# DEBUGSS_DEBUGSS register map
Vendor: Texas Instruments
Registers are 32-bit, read-write, reset 0x0 unless marked. A register's access mark holds for its fields unless they carry their own. Offsets are as the file gives them; [hi:lo] are bit positions; {n}, {i} and the like mark numbered series; <NAME> marks a mode.

## DEBUGSS_DEBUGSS (part 2 of 3)
0x00 DEBUGSS_ONEMCU_APB_BASE ro
  [31:0] ONEMCU_APB_BASE — OneMCU APB Space : Start Address of ROM Table
0xFFC DEBUGSS_ONEMCU_APB_BASE_END ro
  [31:0] ONEMCU_APB_BASE_END — OneMCU APB Space : Endt Address of ROM Table
0x1000 DEBUGSS_ONEMCU_CTI_CONTROL
  [31:0] ONEMCU_CTI_CONTROL — http://infocenter.arm.com/help/topic/com.arm.doc.ddi0480e/CHDGDIHE.htmlhttp://infocenter.arm.com/help/topic/com.arm.doc.ddi0480e/CHDHBDIA.html
0x1010 DEBUGSS_ONEMCU_CTI_INTACK wo
  [31:0] ONEMCU_CTI_INTACK — Not Defined
0x1014 DEBUGSS_ONEMCU_CTI_APPSET
  [31:0] ONEMCU_CTI_APPSET — Not Defined
0x1018 DEBUGSS_ONEMCU_CTI_APPCLEAR wo
  [31:0] ONEMCU_CTI_APPCLEAR — Not Defined
0x101C DEBUGSS_ONEMCU_CTI_APPPULSE wo
  [31:0] ONEMCU_CTI_APPPULSE — Not Defined
{0x1020+4i} DEBUGSS_ONEMCU_CTI_INEN{i} (i=0..7)
  [31:0] ONEMCU_CTI_INEN{i} — Not Defined
{0x10A0+4i} DEBUGSS_ONEMCU_CTI_OUTEN{i} (i=0..7)
  [31:0] ONEMCU_CTI_OUTEN{i} — Not Defined
0x1130 DEBUGSS_ONEMCU_CTI_TRIGINSTATUS ro
  [31:0] ONEMCU_CTI_TRIGINSTATUS — Not Defined
0x1134 DEBUGSS_ONEMCU_CTI_TRIGOUTSTATUS ro
  [31:0] ONEMCU_CTI_TRIGOUTSTATUS — Not Defined
0x1138 DEBUGSS_ONEMCU_CTI_CHINSTATUS ro
  [31:0] ONEMCU_CTI_CHINSTATUS — Not Defined
0x113C DEBUGSS_ONEMCU_CTI_CHOUTSTATUS ro
  [31:0] ONEMCU_CTI_CHOUTSTATUS — Not Defined
0x1140 DEBUGSS_ONEMCU_CTI_GATE
  [31:0] ONEMCU_CTI_GATE — Not Defined
0x1144 DEBUGSS_ONEMCU_CTI_ASICCTL
  [31:0] ONEMCU_CTI_ASICCTL — Not Defined
0x1EDC DEBUGSS_ONEMCU_CTI_ITCHINACK wo
  [31:0] ONEMCU_CTI_ITCHINACK — Not Defined
0x1EE0 DEBUGSS_ONEMCU_CTI_ITTRIGINACK wo
  [31:0] ONEMCU_CTI_ITTRIGINACK — Not Defined
0x1EE4 DEBUGSS_ONEMCU_CTI_ITCHOUT wo
  [31:0] ONEMCU_CTI_ITCHOUT — Not Defined
0x1EE8 DEBUGSS_ONEMCU_CTI_ITTRIGOUT wo
  [31:0] ONEMCU_CTI_ITTRIGOUT — Not Defined
0x1EEC DEBUGSS_ONEMCU_CTI_ITCHOUTACK ro
  [31:0] ONEMCU_CTI_ITCHOUTACK — Not Defined
0x1EF0 DEBUGSS_ONEMCU_CTI_ITTRIGOUTACK ro
  [31:0] ONEMCU_CTI_ITTRIGOUTACK — Not Defined
0x1EF4 DEBUGSS_ONEMCU_CTI_ITCHIN ro
  [31:0] ONEMCU_CTI_ITCHIN — Not Defined
0x1EF8 DEBUGSS_ONEMCU_CTI_ITTRIGIN ro
  [31:0] ONEMCU_CTI_ITTRIGIN — Not Defined
0x1F00 DEBUGSS_ONEMCU_CTI_ITCTRL
  [31:0] ONEMCU_CTI_ITCTRL — Not Defined
0x1FA0 DEBUGSS_ONEMCU_CTI_CLAIM_TAG_SET
  [31:0] ONEMCU_CTI_CLAIM_TAG_SET — Not Defined
0x1FA4 DEBUGSS_ONEMCU_CTI_CLAIM_TAG_CLEAR
  [31:0] ONEMCU_CTI_CLAIM_TAG_CLEAR — Not Defined
0x1FB0 DEBUGSS_ONEMCU_CTI_LOCK_ACCESS_REGISTER wo
  [31:0] ONEMCU_CTI_LOCK_ACCESS_REGISTER — Not Defined
0x1FB4 DEBUGSS_ONEMCU_CTI_LOCK_STATUS_REGISTER ro
  [31:0] ONEMCU_CTI_LOCK_STATUS_REGISTER — Not Defined
0x1FB8 DEBUGSS_ONEMCU_CTI_AUTHENTICATION_STATUS ro
  [31:0] ONEMCU_CTI_AUTHENTICATION_STATUS — Not Defined
0x1FC8 DEBUGSS_ONEMCU_CTI_DEVICE_ID ro
  [31:0] ONEMCU_CTI_DEVICE_ID — Not Defined
0x1FCC DEBUGSS_ONEMCU_CTI_DEVICE_TYPE_IDENTIFIER ro
  [31:0] ONEMCU_CTI_DEVICE_TYPE_IDENTIFIER — Not Defined
{0x1FC0+4i} DEBUGSS_ONEMCU_CTI_PERIPHERALID{i} ro (i=4..7)
  [31:0] ONEMCU_CTI_PERIPHERALID{i} — Not Defined
{0x1FE0+4i} DEBUGSS_ONEMCU_CTI_PERIPHERALID{i} ro (i=0..3)
  [31:0] ONEMCU_CTI_PERIPHERALID{i} — Not Defined
{0x1FF0+4i} DEBUGSS_ONEMCU_CTI_COMPONENT_ID{i} ro (i=0..3)
  [31:0] ONEMCU_CTI_COMPONENT_ID{i} — Not Defined
0x2000 DEBUGSS_ONEMCU_TPIU_SPORTSZ ro reset 0xFFFFFFF
  [31:0] ONEMCU_TPIU_SPORTSZ — Supported port sizes
0x2004 DEBUGSS_ONEMCU_TPIU_CPORTSZ reset 0x1
  [31:0] ONEMCU_TPIU_CPORTSZ — Current port size
0x2100 DEBUGSS_ONEMCU_TPIU_STRIGM ro reset 0x11F
  [31:0] ONEMCU_TPIU_STRIGM — Supported trigger modes
0x2104 DEBUGSS_ONEMCU_TPIU_TRIGCNT
  [31:0] ONEMCU_TPIU_TRIGCNT — Trigger counter value
0x2108 DEBUGSS_ONEMCU_TPIU_TRIGMUL
  [31:0] ONEMCU_TPIU_TRIGMUL — Trigger multiplier
0x2200 DEBUGSS_ONEMCU_TPIU_STSTPTRN ro reset 0x3000F
  [31:0] ONEMCU_TPIU_STSTPTRN — Supported test pattern/modes
0x2204 DEBUGSS_ONEMCU_TPIU_CTSTPTRN
  [31:0] ONEMCU_TPIU_CTSTPTRN — Current test pattern/mode
0x2208 DEBUGSS_ONEMCU_TPIU_TPRCNTR
  [31:0] ONEMCU_TPIU_TPRCNTR — Test pattern repeat counter
0x2300 DEBUGSS_ONEMCU_TPIU_FFSTS ro reset 0x2
  [31:0] ONEMCU_TPIU_FFSTS — Formatter and flush status
0x2304 DEBUGSS_ONEMCU_TPIU_FFCTRL reset 0x1000
  [31:0] ONEMCU_TPIU_FFCTRL — Formatter and flush control
0x2308 DEBUGSS_ONEMCU_TPIU_FSCNTR reset 0x40
  [31:0] ONEMCU_TPIU_FSCNTR — Formatter synchronization counter
0x2400 DEBUGSS_ONEMCU_TPIU_EXCTLIN ro
  [31:0] ONEMCU_TPIU_EXCTLIN — EXTCTL In Port
0x2404 DEBUGSS_ONEMCU_TPIU_EXCTLOUT
  [31:0] ONEMCU_TPIU_EXCTLOUT — EXTCTL Out Port
0x2EE4 DEBUGSS_ONEMCU_TPIU_ITTRFLINACK wo
  [31:0] ONEMCU_TPIU_ITTRFLINACK — Integration Register, ITTRFLINACK
0x2EE8 DEBUGSS_ONEMCU_TPIU_ITTRFLIN ro
  [31:0] ONEMCU_TPIU_ITTRFLIN — Integration Register, ITTRFLIN
0x2EEC DEBUGSS_ONEMCU_TPIU_ITATBDATA0 ro
  [31:0] ONEMCU_TPIU_ITATBDATA0 — Integration Register, ITATBDATA0
0x2EF0 DEBUGSS_ONEMCU_TPIU_ITATBCTR2 wo
  [31:0] ONEMCU_TPIU_ITATBCTR2 — Integration Register, ITATBCTR2
0x2EF4 DEBUGSS_ONEMCU_TPIU_ITATBCTR1 ro
  [31:0] ONEMCU_TPIU_ITATBCTR1 — Integration Register, ITATBCTR1
0x2EF8 DEBUGSS_ONEMCU_TPIU_ITATBCTR0 ro
  [31:0] ONEMCU_TPIU_ITATBCTR0 — Integration Register, ITATBCTR0
0x2F00 DEBUGSS_ONEMCU_TPIU_ITCTRL
  [31:0] ONEMCU_TPIU_ITCTRL — Integration Mode Control Register
0x2FA0 DEBUGSS_ONEMCU_TPIU_CLAIMSET reset 0xF
  [31:0] ONEMCU_TPIU_CLAIMSET — Claim Tag Set
0x2FA4 DEBUGSS_ONEMCU_TPIU_CLAIMCLR
  [31:0] ONEMCU_TPIU_CLAIMCLR — Claim Tag Clear
0x2FB0 DEBUGSS_ONEMCU_TPIU_LAR ro
  [31:0] ONEMCU_TPIU_LAR — Lock status
0x2FB4 DEBUGSS_ONEMCU_TPIU_LSR wo
  [31:0] ONEMCU_TPIU_LSR — Lock Access
0x2FB8 DEBUGSS_ONEMCU_TPIU_AUTHSTATUS ro
  [31:0] ONEMCU_TPIU_AUTHSTATUS — Authentication status
0x2FC8 DEBUGSS_ONEMCU_TPIU_DEVID ro reset 0xA0
  [31:0] ONEMCU_TPIU_DEVID — Device ID
0x2FCC DEBUGSS_ONEMCU_TPIU_DEVTYPE ro reset 0x11
  [31:0] ONEMCU_TPIU_DEVTYPE — Device type identifier
0x2FD0 DEBUGSS_ONEMCU_TPIU_PIDR4 ro reset 0x4
  [31:0] ONEMCU_TPIU_PIDR4 — Peripheral ID4
{0x2FC0+4i} DEBUGSS_ONEMCU_TPIU_PIDR{i} ro (i=5..7)
  [31:0] ONEMCU_TPIU_PIDR{i} — Peripheral ID{i}
0x2FE0 DEBUGSS_ONEMCU_TPIU_PIDR0 ro reset 0x12
  [31:0] ONEMCU_TPIU_PIDR0 — Peripheral ID0
0x2FE4 DEBUGSS_ONEMCU_TPIU_PIDR1 ro reset 0xB9
  [31:0] ONEMCU_TPIU_PIDR1 — Peripheral ID1
0x2FE8 DEBUGSS_ONEMCU_TPIU_PIDR2 ro reset 0x3B
  [31:0] ONEMCU_TPIU_PIDR2 — Peripheral ID2
0x2FEC DEBUGSS_ONEMCU_TPIU_PIDR3 ro
  [31:0] ONEMCU_TPIU_PIDR3 — Peripheral ID3
0x2FF0 DEBUGSS_ONEMCU_TPIU_CIDR0 ro reset 0xD
  [31:0] ONEMCU_TPIU_CIDR0 — Component ID0
0x2FF4 DEBUGSS_ONEMCU_TPIU_CIDR1 ro reset 0x90
  [31:0] ONEMCU_TPIU_CIDR1 — Component ID1
0x2FF8 DEBUGSS_ONEMCU_TPIU_CIDR2 ro reset 0x5
  [31:0] ONEMCU_TPIU_CIDR2 — Component ID2
0x2FFC DEBUGSS_ONEMCU_TPIU_CIDR3 ro reset 0xB1
  [31:0] ONEMCU_TPIU_CIDR3 — Component ID3
0x10000 DEBUGSS_APB_EXT_PORT0_ROM
  [31:0] ATB_REPLICATOR_IDFILTER0 — http://infocenter.arm.com/help/topic/com.arm.doc.ddi0480e/CHDFGIED.htmlhttp://infocenter.arm.com/help/topic/com.arm.doc.ddi0480e/CHDBDCII.html
0x11000 DEBUGSS_ATB_REPLICATOR_IDFILTER0
  [31:0] ATB_REPLICATOR_IDFILTER1 — Not Defined
0x11004 DEBUGSS_ATB_REPLICATOR_IDFILTER1 ro
  [31:0] ATB_REPLICATOR_ITATBCTR1 — Not Defined
0x11EF8 DEBUGSS_ATB_REPLICATOR_ITATBCTR1 wo
  [31:0] ATB_REPLICATOR_ITATBCTR0 — Not Defined
0x11EFC DEBUGSS_ATB_REPLICATOR_ITATBCTR0
  [31:0] ATB_REPLICATOR_ITCTRL — Not Defined
0x11F00 DEBUGSS_ATB_REPLICATOR_ITCTRL reset 0xF
  [31:0] ATB_REPLICATOR_CLAIMSET — Not Defined
0x11FA0 DEBUGSS_ATB_REPLICATOR_CLAIMSET
  [31:0] ATB_REPLICATOR_CLAIMCLR — Not Defined
0x11FA4 DEBUGSS_ATB_REPLICATOR_CLAIMCLR wo
  [31:0] ATB_REPLICATOR_LAR — Not Defined
0x11FB0 DEBUGSS_ATB_REPLICATOR_LAR ro reset 0x3
  [31:0] ATB_REPLICATOR_LSR — Not Defined
0x11FB4 DEBUGSS_ATB_REPLICATOR_LSR ro
  [31:0] ATB_REPLICATOR_AUTHSTATUS — Not Defined
0x11FB8 DEBUGSS_ATB_REPLICATOR_AUTHSTATUS ro reset 0x2
  [31:0] ATB_REPLICATOR_DEVID — Not Defined
0x11FC8 DEBUGSS_ATB_REPLICATOR_DEVID ro reset 0x22
  [31:0] ATB_REPLICATOR_DEVTYPE — Not Defined
0x11FCC DEBUGSS_ATB_REPLICATOR_DEVTYPE ro reset 0x4
  [31:0] ATB_REPLICATOR_PIDR4 — Not Defined
0x11FD0 DEBUGSS_ATB_REPLICATOR_PIDR4 ro
  [31:0] ATB_REPLICATOR_RESERVED1 — Not Defined
0x11FD4 DEBUGSS_ATB_REPLICATOR_RESERVED1 ro
  [31:0] ATB_REPLICATOR_RESERVED2 — Not Defined
0x11FD8 DEBUGSS_ATB_REPLICATOR_RESERVED2 ro
  [31:0] ATB_REPLICATOR_RESERVED3 — Not Defined
0x11FDC DEBUGSS_ATB_REPLICATOR_RESERVED3 ro reset 0x9
  [31:0] ATB_REPLICATOR_PIDR0 — Not Defined
0x11FE0 DEBUGSS_ATB_REPLICATOR_PIDR0 ro reset 0xB9
  [31:0] ATB_REPLICATOR_PIDR1 — Not Defined
0x11FE4 DEBUGSS_ATB_REPLICATOR_PIDR1 ro reset 0x1B
  [31:0] ATB_REPLICATOR_PIDR2 — Not Defined
0x11FE8 DEBUGSS_ATB_REPLICATOR_PIDR2 ro
  [31:0] ATB_REPLICATOR_PIDR3 — Not Defined
0x11FEC DEBUGSS_ATB_REPLICATOR_PIDR3 ro reset 0xD
  [31:0] ATB_REPLICATOR_CIDR0 — Not Defined
0x11FF0 DEBUGSS_ATB_REPLICATOR_CIDR0 ro reset 0x90
  [31:0] ATB_REPLICATOR_CIDR1 — Not Defined
0x11FF4 DEBUGSS_ATB_REPLICATOR_CIDR1 ro reset 0x5
  [31:0] ATB_REPLICATOR_CIDR2 — Not Defined
0x11FF8 DEBUGSS_ATB_REPLICATOR_CIDR2 ro reset 0xB1
  [31:0] ATB_REPLICATOR_CIDR3 — Not Defined
0x11FFC DEBUGSS_ATB_REPLICATOR_CIDR3 ro
  [31:0] ETB_RDP — http://infocenter.arm.com/help/topic/com.arm.doc.ddi0480e/CHDIEIAJ.htmlhttp://infocenter.arm.com/help/topic/com.arm.doc.ddi0480e/CHDDBEHG.html
0x12004 DEBUGSS_ETB_RDP ro reset 0x8
  [31:0] ETB_STS — Not Defined
0x1200C DEBUGSS_ETB_STS ro
  [31:0] ETB_RRD — Not Defined
0x12010 DEBUGSS_ETB_RRD
  [31:0] ETB_RRP — Not Defined
0x12014 DEBUGSS_ETB_RRP
  [31:0] ETB_RWP — Not Defined
0x12018 DEBUGSS_ETB_RWP
  [31:0] ETB_TRG — Not Defined
0x1201C DEBUGSS_ETB_TRG
  [31:0] ETB_CTL — Not Defined
0x12020 DEBUGSS_ETB_CTL wo
  [31:0] ETB_RWD — Not Defined
0x12024 DEBUGSS_ETB_RWD ro reset 0x2
  [31:0] ETB_FFSR — Not Defined
0x12300 DEBUGSS_ETB_FFSR
  [31:0] ETB_FFCR — Not Defined
0x12304 DEBUGSS_ETB_FFCR wo
  [31:0] ETB_ITMISCOP0 — Not Defined
0x12EE0 DEBUGSS_ETB_ITMISCOP0 wo
  [31:0] ETB_ITTRFLINACK — Not Defined
0x12EE4 DEBUGSS_ETB_ITTRFLINACK ro
  [31:0] ETB_ITTRFLIN — Not Defined
0x12EE8 DEBUGSS_ETB_ITTRFLIN ro
  [31:0] ETB_ITATBDATA0 — Not Defined
0x12EEC DEBUGSS_ETB_ITATBDATA0 wo
  [31:0] ETB_ITATBCTR2 — Not Defined
0x12EF0 DEBUGSS_ETB_ITATBCTR2 ro
  [31:0] ETB_ITATBCTR1 — Not Defined
0x12EF4 DEBUGSS_ETB_ITATBCTR1 ro
  [31:0] ETB_ITATBCTR0 — Not Defined
0x12EF8 DEBUGSS_ETB_ITATBCTR0
  [31:0] ETB_ITCTRL — Not Defined
0x12F00 DEBUGSS_ETB_ITCTRL reset 0xF
  [31:0] ETB_CLAIMSET — Not Defined
0x12FA0 DEBUGSS_ETB_CLAIMSET
  [31:0] ETB_CLAIMCLR — Not Defined
0x12FA4 DEBUGSS_ETB_CLAIMCLR wo
  [31:0] ETB_LAR — Not Defined
0x12FB0 DEBUGSS_ETB_LAR ro reset 0x3
  [31:0] ETB_LSR — Not Defined
0x12FB4 DEBUGSS_ETB_LSR ro
  [31:0] ETB_AUTHSTATUS — Not Defined
0x12FB8 DEBUGSS_ETB_AUTHSTATUS ro
  [31:0] ETB_DEVID — Not Defined
0x12FC8 DEBUGSS_ETB_DEVID ro reset 0x21
  [31:0] ETB_DEVTYPE — Not Defined
0x12FCC DEBUGSS_ETB_DEVTYPE ro reset 0x4
  [31:0] ETB_PIDR4 — Not Defined
0x12FD0 DEBUGSS_ETB_PIDR4 ro
  [31:0] ETB_RESERVED4 — Not Defined
0x12FD4 DEBUGSS_ETB_RESERVED4 ro
  [31:0] ETB_RESERVED5 — Not Defined
0x12FD8 DEBUGSS_ETB_RESERVED5 ro
  [31:0] ETB_RESERVED6 — Not Defined
0x12FDC DEBUGSS_ETB_RESERVED6 ro reset 0x7
  [31:0] ETB_PIDR0 — Not Defined
0x12FE0 DEBUGSS_ETB_PIDR0 ro reset 0xB9
  [31:0] ETB_PIDR1 — Not Defined
0x12FE4 DEBUGSS_ETB_PIDR1 ro reset 0x3B
  [31:0] ETB_PIDR2 — Not Defined
0x12FE8 DEBUGSS_ETB_PIDR2 ro
  [31:0] ETB_PIDR3 — Not Defined
0x12FEC DEBUGSS_ETB_PIDR3 ro reset 0xD
  [31:0] ETB_CIDR0 — Not Defined
0x12FF0 DEBUGSS_ETB_CIDR0 ro reset 0x90
  [31:0] ETB_CIDR1 — Not Defined
0x12FF4 DEBUGSS_ETB_CIDR1 ro reset 0x5
  [31:0] ETB_CIDR2 — Not Defined
0x12FF8 DEBUGSS_ETB_CIDR2 ro reset 0xB1
  [31:0] ETB_CIDR3 — Not Defined
0x12FFC DEBUGSS_ETB_CIDR3 wo
  [31:0] STMDMASTARTR — ARM? System Trace Macrocell Programmers? ModelArchitecture Specification
0x13C04 DEBUGSS_STMDMASTARTR wo
  [31:0] STMDMASTOPR — ARM? System Trace Macrocell Programmers? ModelArchitecture Specification
0x13C08 DEBUGSS_STMDMASTOPR ro
  [31:0] STMDMASTATR — ARM? System Trace Macrocell Programmers? ModelArchitecture Specification
0x13C0C DEBUGSS_STMDMASTATR 8-bit
  [3:2] SENS — Determines the sensitivity of the DMA request to the current buffer level in the STM:0b00 Buffer is <25% full.0b01 Buffer is <50% full.0b10 Buffer is <75% full.0b11 Buffer is <100% full.
0x13C10 DEBUGSS_STMDMACTLR ro reset 0x2
  [31:0] STMDMAIDR — ARM? System Trace Macrocell Programmers? ModelArchitecture Specification
0x13CFC DEBUGSS_STMDMAIDR
  [31:0] STMHEER — ARM? System Trace Macrocell Programmers? ModelArchitecture Specification
0x13D00 DEBUGSS_STMHEER
  [31:0] STMHETER — ARM? System Trace Macrocell Programmers? ModelArchitecture Specification
0x13D20 DEBUGSS_STMHETER
  [31:0] STMHEBSR — ARM? System Trace Macrocell Programmers? ModelArchitecture Specification
0x13D60 DEBUGSS_STMHEBSR
  [31:0] STMHEMCR — ARM? System Trace Macrocell Programmers? ModelArchitecture Specification
0x13D64 DEBUGSS_STMHEMCR 8-bit
  [7:0] EXTMUX — Specifies the value that the optional external multiplexing logic uses to select the hardware events to connectto the STM.The value of this register is output from the STM on the HEEXTMUX[7:0] signals. The behavior of themultiplexing logic is IMPLEMENTATION DEFINED.This field is reset to zero.
0x13D68 DEBUGSS_STMHEEXTMUXR 16-bit ro reset 0x80
  [15:0] MASTER — The STPv2 master number for the hardware event trace:0x80 Hardware events are associated with master ID 0x80.
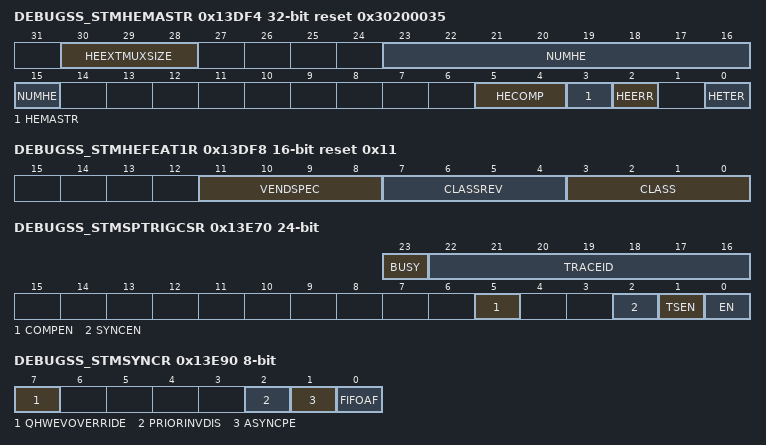
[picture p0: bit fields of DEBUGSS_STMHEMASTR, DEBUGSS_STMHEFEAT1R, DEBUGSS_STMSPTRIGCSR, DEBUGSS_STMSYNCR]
0x13DF4 DEBUGSS_STMHEMASTR ro reset 0x30200035
  [30:28] HEEXTMUXSIZE — The size of the STMHEEXTMUXR.EXTMUX bit field:0b011 8 bits wide.
  [23:15] NUMHE — The number of hardware events supported by the STM:0b001000000 64 hardware events.
  [5:4] HECOMP — Data compression on hardware event tracing support:0b11 Programmable data compression support. The STM implements theSTMHEMCR.COMPEN bit.
  [3] HEMASTR — Specifies the STMHEMASTR support:0b0 The STMHEMASTR is read-only.
  [2] HEERR — Hardware event error detection support:0b1 Implemented. The STM implements the STMHEMCR.ERRDETECT bit.
  [0] HETER — Specifies the STMHETER support:0b1 Implemented.
0x13DF8 DEBUGSS_STMHEFEAT1R 16-bit ro reset 0x11
  [11:8] VENDSPEC — Identifies vendor-specific modifications or mappings:0b0000 Vendor-specific information.
  [7:4] CLASSREV — Identifies the revision of the programmers model:0b0001 Revision.
  [3:0] CLASS — Identifies the programmers model:0b0001 Hardware event control.
0x13DFC DEBUGSS_STMHEIDR
  [31:0] STMSPER — ARM? System Trace Macrocell Programmers? ModelArchitecture Specification
0x13E00 DEBUGSS_STMSPER
  [31:0] STMSPTER — ARM? System Trace Macrocell Programmers? ModelArchitecture Specification
0x13E20 DEBUGSS_STMSPTER
  [31:0] STMSPSCR — ARM? System Trace Macrocell Programmers? ModelArchitecture Specification
0x13E60 DEBUGSS_STMSPSCR
  [31:0] STMSPMSCR — ARM? System Trace Macrocell Programmers? ModelArchitecture Specification
0x13E64 DEBUGSS_STMSPMSCR
  [31:0] STMSPOVERRIDER — ARM? System Trace Macrocell Programmers? ModelArchitecture Specification
0x13E68 DEBUGSS_STMSPOVERRIDER
  [31:0] STMSPMOVERRIDER — ARM? System Trace Macrocell Programmers? ModelArchitecture Specification
0x13E6C DEBUGSS_STMSPMOVERRIDER
  [31:0] STMSPTRIGCSR — ARM? System Trace Macrocell Programmers? ModelArchitecture Specification
0x13E70 DEBUGSS_STMSPTRIGCSR 24-bit
  [23] BUSY — Indicates whether the STM is busy, for example the STM trace FIFO is not empty:0b0 Not busy.0b1 Busy.
  [22:16] TRACEID — ATB trace ID. Setting this value to all zeroes or to a value greater than 0x6F might result in UNPREDICTABLEtracing. Reset value of this bit field is UNKNOWN.
  [5] COMPEN — Compression enable for stimulus ports:0b0 Disabled, the STM transmits data transfers based on the size of the transaction.0b1 Enabled, the STM compresses data transfers to save bandwidth.
  [2] SYNCEN — The STM implements the STMSYNCR, so this bit is Read As One.0b1 The STM implements the STMSYNCR.
  [1] TSEN — Determines whether to ignore timestamp requests:0b0 Disable timestamping. The STM ignores requests for timestamp generation, and treatsstimulus port writes that select timestamping as if timestamping were not selected.0b1 Enable timestamping. If stimulus writes select timestamping, the STM outputs a timestampaccording to STPv2.
  [0] EN — Global STM enable:0b0 Disabled0b1 Enabled.
0x13E80 DEBUGSS_STMTCSR wo
  [31:0] STMTSSTIMR — ARM? System Trace Macrocell Programmers? ModelArchitecture Specification
0x13E84 DEBUGSS_STMTSSTIMR
  [31:0] STMTSFREQR — ARM? System Trace Macrocell Programmers? ModelArchitecture Specification
0x13E8C DEBUGSS_STMTSFREQR
  [31:0] STMSYNCR — ARM? System Trace Macrocell Programmers? ModelArchitecture Specification
0x13E90 DEBUGSS_STMSYNCR 8-bit
  [7] QHWEVOVERRIDE — Low-power interface override when hardware event tracing is enabled:0b0 The STM can accept a quiescence request on the STM low-power interface whenthe STMHEMCR.EN bit is set to 0b1.0b1 If the STMHEMCR.EN bit is set to 0b1, all quiescence requests on the STMlow-power interface are denied.Reset value is 0b0.
  [2] PRIORINVDIS — Controls arbitration between the AXI interface and the hardware event observation interface duringflush:0b0 Priority inversion. When the AXI flush completes, the hardware event observationinterface gets priority until the hardware event observation interface flushcompletes.0b1 Priority inversion disabled. The AXI always has priority over the hardware eventobservation interface.Reset value is 0b0.
  [1] ASYNCPE — ASYNC priority:0b0 Always lower than trace.0b1 Escalates on second synchronization request.Reset value is 0b0.
  [0] FIFOAF — Auto-flush:0b0 Disabled.0b1 Enabled. The STM automatically drains all data even if the ATB interface is notfully utilized.Reset value is 0b0.
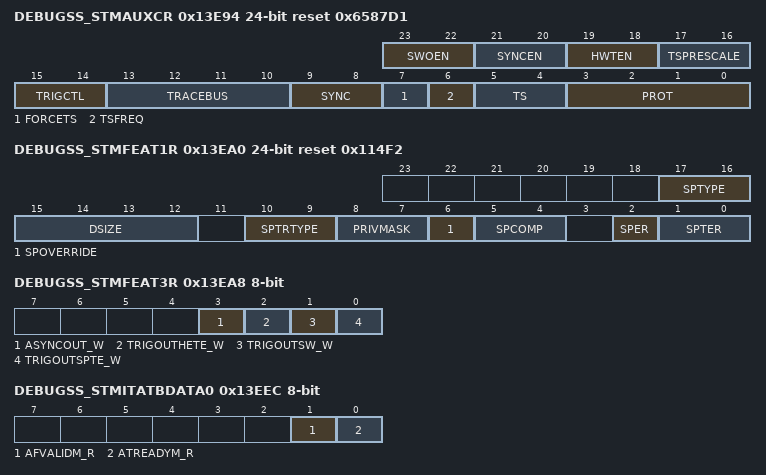
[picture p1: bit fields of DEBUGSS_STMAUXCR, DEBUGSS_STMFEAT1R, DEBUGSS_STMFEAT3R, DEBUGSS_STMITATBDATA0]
0x13E94 DEBUGSS_STMAUXCR 24-bit ro reset 0x6587D1
  [23:22] SWOEN — Specifies the STMTCSR.SWOEN bit support:0b01 Not implemented.
  [21:20] SYNCEN — Specifies the STMTCSR.SYNCEN bit support:0b10 Implemented but always reads as 0b1.
  [19:18] HWTEN — Specifies the STMTCSR.HWTEN bit support:0b01 Not implemented.
  [17:16] TSPRESCALE — Timestamp prescale support:0b01 Not implemented.
  [15:14] TRIGCTL — Trigger control support:0b10 Multi-shot and single-shot triggers supported, the STM implements the STMTRIGCSR.
  [13:10] TRACEBUS — Trace bus support:0b0001 CoreSight ATB plus ATB trigger support implemented, the STM implements theSTMTCSR.TRACEID and STMTRIGCSR.ATBTRIGEN bit fields.
  [9:8] SYNC — Specifies the STMSYNCR support:0b11 Implemented with MODE control.
  [7] FORCETS — Specifies the STMTSSTIMR support:0b1 The STM implements the STMTSSTIMR.FORCETS bit.
  [6] TSFREQ — Timestamp frequency indication configuration:0b1 The STMTSFREQR is read-write.
  [5:4] TS — Timestamp support:0b01 Absolute timestamps implemented.
  [3:0] PROT — Protocol:0b0001 STPv2 protocol.
0x13EA0 DEBUGSS_STMFEAT1R 24-bit ro reset 0x114F2
  [17:16] SPTYPE — Stimulus port type support:0b01 Only extended stimulus ports.
  [15:12] DSIZE — Fundamental data size:0b0001 64-bit data.
  [10:9] SPTRTYPE — Stimulus port transaction type support:0b10 Both invariant timing and guaranteed transactions.
  [8:7] PRIVMASK — Specifies the STMPRIVMASKR support:0b01 Not implemented.
  [6] SPOVERRIDE — Specifies the STMSPOVERRIDER support:0b1 STMSPOVERRIDER and STMSPMOVERRIDER implemented.
  [5:4] SPCOMP — Data compression on stimulus ports support:0b11 Data compression support is programmable, the STM implements theSTMTCSR.COMPEN bit.
  [2] SPER — Specifies the STMSPER presence:0b0 Implemented.
  [1:0] SPTER — Specifies the STMSPTER support:0b10 Implemented.
0x13EA4 DEBUGSS_STMFEAT2R 8-bit ro reset 0x7F
  [6:0] NUMMAST — The number of stimulus port masters implemented minus 1:0b1111111 128 ports.
0x13EA8 DEBUGSS_STMFEAT3R 8-bit wo
  [3] ASYNCOUT_W — Sets the value of the ASYNCOUT output signal in integration mode:0b1 Drive logic 0b1.0b0 Drive logic 0b0.
  [2] TRIGOUTHETE_W — Sets the value of the TRIGOUTHETE output signal in integration mode:0b1 Drive logic 0b1.0b0 Drive logic 0b0.
  [1] TRIGOUTSW_W — Sets the value of the TRIGOUTSW output signal in integration mode:0b1 Drive logic 0b1.0b0 Drive logic 0b0.
  [0] TRIGOUTSPTE_W — Sets the value of the TRIGOUTSPTE output signal in integration mode:0b1 Drive logic 0b1.0b0 Drive logic 0b0.
0x13EE8 DEBUGSS_STMITTRIGGER 8-bit wo
  [8] ATDATAM63_W — Sets the value of the ATDATAM[63] output signal:0b1 Drive logic 0b1.0b0 Drive logic 0b0.
  [7] ATDATAM55_W — Sets the value of the ATDATAM[55] output signal:0b1 Drive logic 0b1.0b0 Drive logic 0b0.
  [6] ATDATAM47_W — Sets the value of the ATDATAM[47] output signal:0b1 Drive logic 0b1.0b0 Drive logic 0b0.
  [5] ATDATAM39_W — Sets the value of the ATDATAM[39] output signal:0b1 Drive logic 0b1.0b0 Drive logic 0b0.
  [4] ATDATAM31_W — Sets the value of the ATDATAM[31] output signal:0b1 Drive logic 0b1.0b0 Drive logic 0b0.
  [3] ATDATAM23_W — Sets the value of the ATDATAM[23] output signal:0b1 Drive logic 0b1.0b0 Drive logic 0b0.
  [2] ATDATAM15_W — Sets the value of the ATDATAM[15] output signal:0b1 Drive logic 0b1.0b0 Drive logic 0b0.
  [1] ATDATAM7_W — Sets the value of the ATDATAM[7] output signal:0b1 Drive logic 0b1.0b0 Drive logic 0b0.
  [0] ATDATAM0_W — Sets the value of the ATDATAM[0] output signal:0b1 Drive logic 0b1.0b0 Drive logic 0b0.
0x13EEC DEBUGSS_STMITATBDATA0 8-bit ro
  [1] AFVALIDM_R — Reads the value of the AFVALIDM input signal:0b1 The signal is at logic 0b1.0b0 The signal is at logic 0b0.
  [0] ATREADYM_R — Reads the value of the ATREADYM input signal:0b1 The signal is at logic 0b1.0b0 The signal is at logic 0b0.
0x13EF0 DEBUGSS_STMITATBCTR2 8-bit wo
  [6:0] ATIDM_W — Sets the value of the ATIDM output signal.
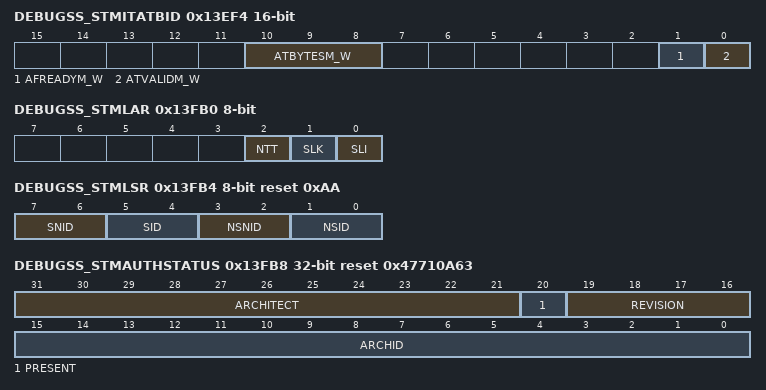
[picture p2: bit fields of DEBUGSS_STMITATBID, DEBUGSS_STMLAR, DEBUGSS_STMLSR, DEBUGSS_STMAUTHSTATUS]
0x13EF4 DEBUGSS_STMITATBID 16-bit wo
  [10:8] ATBYTESM_W — Sets the value of the ATBYTESM output signal:0b111 Drive logic 0b111.0b110 Drive logic 0b110.0b101 Drive logic 0b101.0b100 Drive logic 0b100.0b011 Drive logic 0b011.0b010 Drive logic 0b010.0b001 Drive logic 0b001.0b000 Drive logic 0b000.
  [1] AFREADYM_W — Sets the value of the AFREADYM output signal:0b1 Drive logic 0b1.0b0 Drive logic 0b0.
  [0] ATVALIDM_W — Sets the value of the ATVALIDM output signal:0b1 Drive logic 0b1.0b0 Drive logic 0b0.
0x13EF8 DEBUGSS_STMITATBCTR0 size not given
  [0] IME — Enables the component to switch between functional and integration mode.0b1 Enable integration mode.0b0 Disable integration mode.
0x13F00 DEBUGSS_STMITCTRL reset 0xF
  [31:0] STMCLAIMSET — ARM? System Trace Macrocell Programmers? ModelArchitecture Specification
0x13FA0 DEBUGSS_STMCLAIMSET
  [31:0] STMCLAIMCLR — ARM? System Trace Macrocell Programmers? ModelArchitecture Specification
0x13FA4 DEBUGSS_STMCLAIMCLR wo
  [31:0] KEY — Ignores writes when the PADDRDBG31 signal is HIGH.When the PADDRDBG31 signal is LOW, a write of 0xC5ACCE55 unlocks the lock control mechanism, enablingfurther writes with the PADDRDBG31 signal LOW.Other values lock the lock control mechanism, preventing further writes with the PADDRDBG31 signal LOW,except to the STMLAR.
0x13FB0 DEBUGSS_STMLAR 8-bit wo
  [2] NTT — Indicates whether the component implements the STMLAR as 8 bit or 32 bit.0b0 32 bit.
  [1] SLK — Returns the current status of the lock.0b0 Enables write access to the STM. For read accesses to the STMLSR when the PADDRDBG31signal is HIGH, this bit is always 0b0.0b1 Blocks write access to the STM. The STM ignores all write accesses to the registers when thePADDRDBG31 signal is LOW. Reads are permitted
  [0] SLI — Indicates that a lock control mechanism exists for the device.0b0 No lock control mechanism exists. The STM ignores writes to the STMLAR. For read accessesto the STMLSR when the PADDRDBG31 signal is HIGH, this bit is always 0b0.0b1 Lock control mechanism is present. For read accesses to the STMLSR when the PADDRDBG31signal is LOW, this bit is always 0b1.
0x13FB4 DEBUGSS_STMLSR 8-bit ro reset 0xAA
  [7:6] SNID — Indicates the security level for Secure non-invasive debug:0b10 Disabled.0b11 Enabled.
  [5:4] SID — Indicates the security level for Secure invasive debug:0b10 Disabled.0b11 Enabled.
  [3:2] NSNID — Indicates the security level for Non-secure non-invasive debug:0b10 Disabled.0b11 Enabled.
  [1:0] NSID — Indicates the security level for Non-secure invasive debug:0b10 Disabled.0b11 Enabled.
0x13FB8 DEBUGSS_STMAUTHSTATUS ro reset 0x47710A63
  [31:21] ARCHITECT — Defines the architect of the component:Bits[31:28] Indicates the JEP106 continuation code.Bits[27:21] Indicates the JEP106 identification code.See the Standard Manufacturer?s Identification Code for information about JEP106. For the STM-500,ARM is the architect, and this 11-bit field returns 0x23B.
  [20] PRESENT — Indicates the presence of the STMDEVARCH register:0b1 The STMDEVARCH register is present.
  [19:16] REVISION — Architecture revision. Returns the revision of the architecture that the ARCHID field specifies. For theSTM, this value is 0x1, indicating the STMv1.1 architecture.
  [15:0] ARCHID — Architecture ID. Returns a value that identifies the architecture of the component. For the STM, this valueis 0x0A63, indicating the STMv1.1 architecture.
0x13FBC DEBUGSS_STMDEVARCH 16-bit ro reset 0x10000
  [16:0] NUMSP — Indicates the number of stimulus ports implemented.0x10000 65536
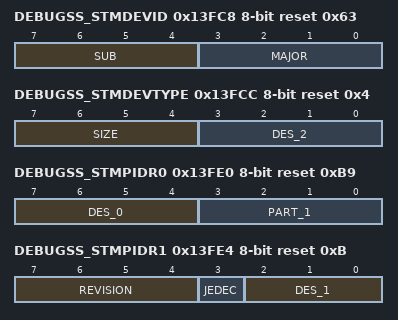
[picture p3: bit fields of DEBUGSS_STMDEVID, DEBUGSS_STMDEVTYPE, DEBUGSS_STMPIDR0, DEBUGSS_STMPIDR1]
0x13FC8 DEBUGSS_STMDEVID 8-bit ro reset 0x63
  [7:4] SUB — Sub-classification within the major category:0b0110 The component generates trace based on software and hardware stimulus
  [3:0] MAJOR — Major classification grouping for the debug or trace component:0b0011 The component is a trace source.
0x13FCC DEBUGSS_STMDEVTYPE 8-bit ro reset 0x4
  [7:4] SIZE — This 4-bit value indicates the total contiguous size of the memory window used by the component in powers oftwo from the standard 4KB. If a component only requires the standard 4KB, this bit field must read as 0x0, 4KBonly. For 8KB set to 0x1, for 16KB set to 0x2, for 32KB set to 0x3, and so on.0x0 The device only occupies 4KB of memory.
  [3:0] DES_2 — JEDEC continuation code indicating the designer of the component, together with the identity code.0x4 ARM JEDEC identity code is on the fifth bank.
0x13FD0 DEBUGSS_STMPIDR4 8-bit ro reset 0x63
  [7:0] PART_0 — Bits [7:0] of the component part number, specified by the designer of the component.0b01100011 Lowest eight bits of the part number, 0x963.
0x13FE0 DEBUGSS_STMPIDR0 8-bit ro reset 0xB9
  [7:4] DES_0 — Bits [3:0] of the JEDEC identity code indicating the designer of the component, together with the continuationcode.0b1011 Lowest four bits of the JEP106 identity code.
  [3:0] PART_1 — Bits [11:8] of the component part number, specified by the designer of the component.0b1001 Upper four bits of the part number, 0x963.
0x13FE4 DEBUGSS_STMPIDR1 8-bit ro reset 0xB
  [7:4] REVISION — An incremental value starting at 0x0 for the first design of this component. The value increases by one for bothmajor and minor revisions and is used as a look-up to establish the exact major and minor revision.0b0000 The device is at r0p0
  [3] JEDEC — Indicates the use of a JEDEC assigned value. This bit is always set.0b1 The designer ID is specified by JEDEC (http://www.jedec.org).
  [2:0] DES_1 — Bits [6:4] of the JEDEC identity code indicating the designer of the component, together with the continuationcode.0b011 Upper three bits of the JEP106 identity code
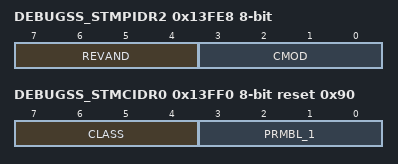
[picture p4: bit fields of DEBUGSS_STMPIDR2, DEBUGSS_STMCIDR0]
0x13FE8 DEBUGSS_STMPIDR2 8-bit ro
  [7:4] REVAND — Indicates minor errata fixes specific to the design, for example metal fixes after implementation. In most casesthis field is zero. ARM recommends that the component designers ensure that the bit field can be changed by ametal fix if required, for example by driving the bit field from registers that reset to zero.0x0 No metal fixes in the component.
  [3:0] CMOD — Where the component is reusable IP, this value indicates whether the customer has modified the behavior of thecomponent. In most cases this field is zero.0x0 No modifications made.
0x13FEC DEBUGSS_STMPIDR3 8-bit ro reset 0xD
  [7:0] PRMBL_0 — Contains bits [31:21] of the component identification.0x0D Identification value.
0x13FF0 DEBUGSS_STMCIDR0 8-bit ro reset 0x90
  [7:4] CLASS — Class of the component, for example, the ROM table or CoreSight component.0x9 Indicates the component is a CoreSight component.
  [3:0] PRMBL_1 — Contains bits [19:16] of the component identification.0x0 Identification value.
0x13FF4 DEBUGSS_STMCIDR1 8-bit ro reset 0x5
  [7:0] PRMBL_2 — Contains bits [15:8] of the component identification.0x05 Identification value.
0x13FF8 DEBUGSS_STMCIDR2 8-bit ro reset 0xB1
  [7:0] PRMBL_3 — Contains bits [7:0] of the component identification.0xB1 Identification value.
0x13FFC DEBUGSS_STMCIDR3
  [31:0] STM_CTI_CONTROL — Not Defined
0x14000 DEBUGSS_STM_CTI_CONTROL wo
  [31:0] STM_CTI_INTACK — Not Defined
0x14010 DEBUGSS_STM_CTI_INTACK
  [31:0] STM_CTI_APPSET — Not Defined
0x14014 DEBUGSS_STM_CTI_APPSET wo
  [31:0] STM_CTI_APPCLEAR — Not Defined
0x14018 DEBUGSS_STM_CTI_APPCLEAR wo
  [31:0] STM_CTI_APPPULSE — Not Defined
0x1401C DEBUGSS_STM_CTI_APPPULSE
  [31:0] STM_CTI_INEN0 — Not Defined
{0x14020+4i} DEBUGSS_STM_CTI_INEN{i} (i=0..6)
  [31:0] STM_CTI_INEN{i+1} — Not Defined
0x1403C DEBUGSS_STM_CTI_INEN7
  [31:0] STM_CTI_OUTEN0 — Not Defined
{0x140A0+4i} DEBUGSS_STM_CTI_OUTEN{i} (i=0..6)
  [31:0] STM_CTI_OUTEN{i+1} — Not Defined
0x140BC DEBUGSS_STM_CTI_OUTEN7 ro
  [31:0] STM_CTI_TRIGINSTATUS — Not Defined
0x14130 DEBUGSS_STM_CTI_TRIGINSTATUS ro
  [31:0] STM_CTI_TRIGOUTSTATUS — Not Defined
0x14134 DEBUGSS_STM_CTI_TRIGOUTSTATUS ro
  [31:0] STM_CTI_CHINSTATUS — Not Defined
0x14138 DEBUGSS_STM_CTI_CHINSTATUS ro
  [31:0] STM_CTI_CHOUTSTATUS — Not Defined
0x1413C DEBUGSS_STM_CTI_CHOUTSTATUS
  [31:0] STM_CTI_GATE — Not Defined
0x14140 DEBUGSS_STM_CTI_GATE
  [31:0] STM_CTI_ASICCTL — Not Defined
0x14144 DEBUGSS_STM_CTI_ASICCTL wo
  [31:0] STM_CTI_ITCHINACK — Not Defined
0x14EDC DEBUGSS_STM_CTI_ITCHINACK wo
  [31:0] STM_CTI_ITTRIGINACK — Not Defined
0x14EE0 DEBUGSS_STM_CTI_ITTRIGINACK wo
  [31:0] STM_CTI_ITCHOUT — Not Defined
0x14EE4 DEBUGSS_STM_CTI_ITCHOUT wo
  [31:0] STM_CTI_ITTRIGOUT — Not Defined
0x14EE8 DEBUGSS_STM_CTI_ITTRIGOUT ro
  [31:0] STM_CTI_ITCHOUTACK — Not Defined
0x14EEC DEBUGSS_STM_CTI_ITCHOUTACK ro
  [31:0] STM_CTI_ITTRIGOUTACK — Not Defined
0x14EF0 DEBUGSS_STM_CTI_ITTRIGOUTACK ro
  [31:0] STM_CTI_ITCHIN — Not Defined
0x14EF4 DEBUGSS_STM_CTI_ITCHIN ro
  [31:0] STM_CTI_ITTRIGIN — Not Defined
0x14EF8 DEBUGSS_STM_CTI_ITTRIGIN
  [31:0] STM_CTI_ITCTRL — Not Defined
0x14F00 DEBUGSS_STM_CTI_ITCTRL
  [31:0] STM_CTI_CLAIM_TAG_SET — Not Defined
0x14FA0 DEBUGSS_STM_CTI_CLAIM_TAG_SET
  [31:0] STM_CTI_CLAIM_TAG_CLEAR — Not Defined
0x14FA4 DEBUGSS_STM_CTI_CLAIM_TAG_CLEAR wo
  [31:0] STM_CTI_LOCK_ACCESS_REGISTER — Not Defined
0x14FB0 DEBUGSS_STM_CTI_LOCK_ACCESS_REGISTER ro
  [31:0] STM_CTI_LOCK_STATUS_REGISTER — Not Defined
0x14FB4 DEBUGSS_STM_CTI_LOCK_STATUS_REGISTER ro
  [31:0] STM_CTI_AUTHENTICATION_STATUS — Not Defined
0x14FB8 DEBUGSS_STM_CTI_AUTHENTICATION_STATUS ro
  [31:0] STM_CTI_DEVICE_ID — Not Defined
0x14FC8 DEBUGSS_STM_CTI_DEVICE_ID ro
  [31:0] STM_CTI_DEVICE_TYPE_IDENTIFIER — Not Defined
0x14FCC DEBUGSS_STM_CTI_DEVICE_TYPE_IDENTIFIER ro
  [31:0] STM_CTI_PERIPHERALID4 — Not Defined
{0x14FC0+4i} DEBUGSS_STM_CTI_PERIPHERALID{i} ro (i=4..6)
  [31:0] STM_CTI_PERIPHERALID{i+1} — Not Defined
0x14FDC DEBUGSS_STM_CTI_PERIPHERALID7 ro
  [31:0] STM_CTI_PERIPHERALID0 — Not Defined
{0x14FE0+4i} DEBUGSS_STM_CTI_PERIPHERALID{i} ro (i=0..2)
  [31:0] STM_CTI_PERIPHERALID{i+1} — Not Defined
0x14FEC DEBUGSS_STM_CTI_PERIPHERALID3 ro
  [31:0] STM_CTI_COMPONENT_ID0 — Not Defined
{0x14FF0+4i} DEBUGSS_STM_CTI_COMPONENT_ID{i} ro (i=0..2)
  [31:0] STM_CTI_COMPONENT_ID{i+1} — Not Defined
0x14FFC DEBUGSS_STM_CTI_COMPONENT_ID3
  [31:0] HSM_CM4_CTI_CONTROL — http://infocenter.arm.com/help/topic/com.arm.doc.ddi0480e/CHDGDIHE.htmlhttp://infocenter.arm.com/help/topic/com.arm.doc.ddi0480e/CHDHBDIA.html
0x15000 DEBUGSS_HSM_CM4_CTI_CONTROL wo
  [31:0] HSM_CM4_CTI_INTACK — Not Defined
0x15010 DEBUGSS_HSM_CM4_CTI_INTACK
  [31:0] HSM_CM4_CTI_APPSET — Not Defined
0x15014 DEBUGSS_HSM_CM4_CTI_APPSET wo
  [31:0] HSM_CM4_CTI_APPCLEAR — Not Defined
0x15018 DEBUGSS_HSM_CM4_CTI_APPCLEAR wo
  [31:0] HSM_CM4_CTI_APPPULSE — Not Defined
0x1501C DEBUGSS_HSM_CM4_CTI_APPPULSE
  [31:0] HSM_CM4_CTI_INEN0 — Not Defined
{0x15020+4i} DEBUGSS_HSM_CM4_CTI_INEN{i} (i=0..6)
  [31:0] HSM_CM4_CTI_INEN{i+1} — Not Defined
0x1503C DEBUGSS_HSM_CM4_CTI_INEN7
  [31:0] HSM_CM4_CTI_OUTEN0 — Not Defined
{0x150A0+4i} DEBUGSS_HSM_CM4_CTI_OUTEN{i} (i=0..6)
  [31:0] HSM_CM4_CTI_OUTEN{i+1} — Not Defined
0x150BC DEBUGSS_HSM_CM4_CTI_OUTEN7 ro
  [31:0] HSM_CM4_CTI_TRIGINSTATUS — Not Defined
0x15130 DEBUGSS_HSM_CM4_CTI_TRIGINSTATUS ro
  [31:0] HSM_CM4_CTI_TRIGOUTSTATUS — Not Defined
0x15134 DEBUGSS_HSM_CM4_CTI_TRIGOUTSTATUS ro
  [31:0] HSM_CM4_CTI_CHINSTATUS — Not Defined
0x15138 DEBUGSS_HSM_CM4_CTI_CHINSTATUS ro
  [31:0] HSM_CM4_CTI_CHOUTSTATUS — Not Defined
0x1513C DEBUGSS_HSM_CM4_CTI_CHOUTSTATUS
  [31:0] HSM_CM4_CTI_GATE — Not Defined
0x15140 DEBUGSS_HSM_CM4_CTI_GATE
  [31:0] HSM_CM4_CTI_ASICCTL — Not Defined
0x15144 DEBUGSS_HSM_CM4_CTI_ASICCTL wo
  [31:0] HSM_CM4_CTI_ITCHINACK — Not Defined
0x15EDC DEBUGSS_HSM_CM4_CTI_ITCHINACK wo
  [31:0] HSM_CM4_CTI_ITTRIGINACK — Not Defined
0x15EE0 DEBUGSS_HSM_CM4_CTI_ITTRIGINACK wo
  [31:0] HSM_CM4_CTI_ITCHOUT — Not Defined
0x15EE4 DEBUGSS_HSM_CM4_CTI_ITCHOUT wo
  [31:0] HSM_CM4_CTI_ITTRIGOUT — Not Defined
0x15EE8 DEBUGSS_HSM_CM4_CTI_ITTRIGOUT ro
  [31:0] HSM_CM4_CTI_ITCHOUTACK — Not Defined
0x15EEC DEBUGSS_HSM_CM4_CTI_ITCHOUTACK ro
  [31:0] HSM_CM4_CTI_ITTRIGOUTACK — Not Defined
0x15EF0 DEBUGSS_HSM_CM4_CTI_ITTRIGOUTACK ro
  [31:0] HSM_CM4_CTI_ITCHIN — Not Defined
0x15EF4 DEBUGSS_HSM_CM4_CTI_ITCHIN ro
  [31:0] HSM_CM4_CTI_ITTRIGIN — Not Defined
0x15EF8 DEBUGSS_HSM_CM4_CTI_ITTRIGIN
  [31:0] HSM_CM4_CTI_ITCTRL — Not Defined
0x15F00 DEBUGSS_HSM_CM4_CTI_ITCTRL
  [31:0] HSM_CM4_CTI_CLAIM_TAG_SET — Not Defined
0x15FA0 DEBUGSS_HSM_CM4_CTI_CLAIM_TAG_SET
  [31:0] HSM_CM4_CTI_CLAIM_TAG_CLEAR — Not Defined
0x15FA4 DEBUGSS_HSM_CM4_CTI_CLAIM_TAG_CLEAR wo
  [31:0] HSM_CM4_CTI_LOCK_ACCESS_REGISTER — Not Defined
0x15FB0 DEBUGSS_HSM_CM4_CTI_LOCK_ACCESS_REGISTER ro
  [31:0] HSM_CM4_CTI_LOCK_STATUS_REGISTER — Not Defined
0x15FB4 DEBUGSS_HSM_CM4_CTI_LOCK_STATUS_REGISTER ro
  [31:0] HSM_CM4_CTI_AUTHENTICATION_STATUS — Not Defined
0x15FB8 DEBUGSS_HSM_CM4_CTI_AUTHENTICATION_STATUS ro
  [31:0] HSM_CM4_CTI_DEVICE_ID — Not Defined
0x15FC8 DEBUGSS_HSM_CM4_CTI_DEVICE_ID ro
  [31:0] HSM_CM4_CTI_DEVICE_TYPE_IDENTIFIER — Not Defined
0x15FCC DEBUGSS_HSM_CM4_CTI_DEVICE_TYPE_IDENTIFIER ro
  [31:0] HSM_CM4_CTI_PERIPHERALID4 — Not Defined
{0x15FC0+4i} DEBUGSS_HSM_CM4_CTI_PERIPHERALID{i} ro (i=4..6)
  [31:0] HSM_CM4_CTI_PERIPHERALID{i+1} — Not Defined
0x15FDC DEBUGSS_HSM_CM4_CTI_PERIPHERALID7 ro
  [31:0] HSM_CM4_CTI_PERIPHERALID0 — Not Defined
{0x15FE0+4i} DEBUGSS_HSM_CM4_CTI_PERIPHERALID{i} ro (i=0..2)
  [31:0] HSM_CM4_CTI_PERIPHERALID{i+1} — Not Defined
0x15FEC DEBUGSS_HSM_CM4_CTI_PERIPHERALID3 ro
  [31:0] HSM_CM4_CTI_COMPONENT_ID0 — Not Defined
{0x15FF0+4i} DEBUGSS_HSM_CM4_CTI_COMPONENT_ID{i} ro (i=0..2)
  [31:0] HSM_CM4_CTI_COMPONENT_ID{i+1} — Not Defined
0x15FFC DEBUGSS_HSM_CM4_CTI_COMPONENT_ID3
  [31:0] MSS_R5SS0_APB_DBGDIDR — http://infocenter.arm.com/help/topic/com.arm.doc.ddi0363e/Cegejeeb.htmlDebug Identification Register
